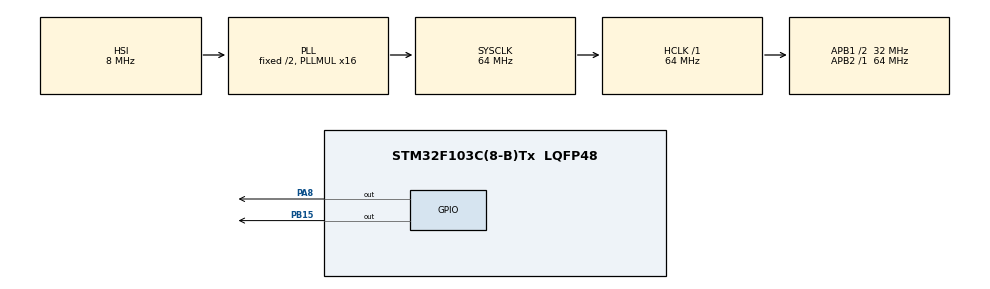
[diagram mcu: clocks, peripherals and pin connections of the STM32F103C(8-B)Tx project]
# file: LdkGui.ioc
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Mcu.Family=STM32F1
Mcu.Name=STM32F103C(8-B)Tx
Mcu.Package=LQFP48
NVIC.PriorityGroup=NVIC_PRIORITYGROUP_4
PA13.Mode=Serial_Wire
PA13.Signal=SYS_JTMS-SWDIO
PA14.Mode=Serial_Wire
PA14.Signal=SYS_JTCK-SWCLK
PA8.Signal=GPIO_Output
PB15.Signal=GPIO_Output
PD0-OSC_IN.Mode=HSE-External-Oscillator
PD0-OSC_IN.Signal=RCC_OSC_IN
PD1-OSC_OUT.Mode=HSE-External-Oscillator
PD1-OSC_OUT.Signal=RCC_OSC_OUT
ProjectManager.HeapSize=0x200
ProjectManager.StackSize=0x400
ProjectManager.TargetToolchain=MDK-ARM V5
RCC.AHBFreq_Value=64000000
RCC.APB1CLKDivider=RCC_HCLK_DIV2
RCC.APB1Freq_Value=32000000
RCC.APB1TimFreq_Value=64000000
RCC.APB2Freq_Value=64000000
RCC.APB2TimFreq_Value=64000000
RCC.HCLKFreq_Value=64000000
RCC.PLLMUL=RCC_PLL_MUL16
RCC.SYSCLKFreq_VALUE=64000000
RCC.SYSCLKSource=RCC_SYSCLKSOURCE_PLLCLK
RCC.USBFreq_Value=64000000
board=custom

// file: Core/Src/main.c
/* USER CODE BEGIN Header */
/**
  ******************************************************************************
  * @file           : main.c
  * @brief          : Main program body
  ******************************************************************************
  * @attention
  *
  * <h2><center>&copy; Copyright (c) 2022 STMicroelectronics.
  * All rights reserved.</center></h2>
  *
  * This software component is licensed by ST under BSD 3-Clause license,
  * the "License"; You may not use this file except in compliance with the
  * License. You may obtain a copy of the License at:
  *                        opensource.org/licenses/BSD-3-Clause
  *
  ******************************************************************************
  */
/* USER CODE END Header */
#include "main.h"
#include "gpio.h"

void SystemClock_Config(void);

/* USER CODE BEGIN 0 */
#include "oled.h"
#include "bmp.h"
#include "lkdGui.h"
extern  lkdFont defaultFont;
void LkdGuiDemo(void)
{
	static lkdWin test1Win,MainWin;
		OLED_Init();				//初始化OLED

	void defaultFontInit(void);
	defaultFontInit();/* 字库初始化 */

	/* -----------显示按键--------------- */
	lkdButton tButton;
	tButton.x = 10;
	tButton.y = 10;
	tButton.wide = 40;
	tButton.high = 30;
	tButton.name = "Ok";
	tButton.flag = BUTTON_DOWN;//
	GuiButton(&tButton);
	GuiUpdateDisplayAll();

	lkdButton tButton1;
	tButton1.x = 60;
	tButton1.y = 10;
	tButton1.wide = 40;
	tButton1.high = 30;
	tButton1.name = "Cancel";
	tButton1.flag = BUTTON_DOWN;//
	GuiButton(&tButton1);
	GuiUpdateDisplayAll();
	HAL_Delay(2000);
	GuiClearScreen(0);
	HAL_Delay(2000);
	GuiClearScreen(0);
	/* -----------显示按键--------------- */

	while(1)
	{
		//循环调用窗口处理
		GuiWinDisplay();
	}
	/* -----------显示菜单--------------- */
}

/* USER CODE END 0 */

int main(void)
{

  /* MCU Configuration--------------------------------------------------------*/

  /* Reset of all peripherals, Initializes the Flash interface and the Systick. */
  HAL_Init();

  /* Configure the system clock */
  SystemClock_Config();

  /* Initialize all configured peripherals */
  MX_GPIO_Init();
  /* USER CODE BEGIN 2 */
	LkdGuiDemo();
  /* USER CODE END 2 */

  /* Infinite loop */
  while (1)
  {

  }
}

void SystemClock_Config(void)
{
  RCC_OscInitTypeDef RCC_OscInitStruct = {0};
  RCC_ClkInitTypeDef RCC_ClkInitStruct = {0};

  /** Initializes the RCC Oscillators according to the specified parameters
  * in the RCC_OscInitTypeDef structure.
  */
  RCC_OscInitStruct.OscillatorType = RCC_OSCILLATORTYPE_HSI;
  RCC_OscInitStruct.HSIState = RCC_HSI_ON;
  RCC_OscInitStruct.HSICalibrationValue = RCC_HSICALIBRATION_DEFAULT;
  RCC_OscInitStruct.PLL.PLLState = RCC_PLL_ON;
  RCC_OscInitStruct.PLL.PLLSource = RCC_PLLSOURCE_HSI_DIV2;
  RCC_OscInitStruct.PLL.PLLMUL = RCC_PLL_MUL16;
  if (HAL_RCC_OscConfig(&RCC_OscInitStruct) != HAL_OK)
  {
    Error_Handler();
  }
  /** Initializes the CPU, AHB and APB buses clocks
  */
  RCC_ClkInitStruct.ClockType = RCC_CLOCKTYPE_HCLK|RCC_CLOCKTYPE_SYSCLK
                              |RCC_CLOCKTYPE_PCLK1|RCC_CLOCKTYPE_PCLK2;
  RCC_ClkInitStruct.SYSCLKSource = RCC_SYSCLKSOURCE_PLLCLK;
  RCC_ClkInitStruct.AHBCLKDivider = RCC_SYSCLK_DIV1;
  RCC_ClkInitStruct.APB1CLKDivider = RCC_HCLK_DIV2;
  RCC_ClkInitStruct.APB2CLKDivider = RCC_HCLK_DIV1;

  if (HAL_RCC_ClockConfig(&RCC_ClkInitStruct, FLASH_LATENCY_2) != HAL_OK)
  {
    Error_Handler();
  }
}

void Error_Handler(void)
{
  __disable_irq();
  while (1)
  {
  }
}

/************************ (C) COPYRIGHT STMicroelectronics *****END OF FILE****/
